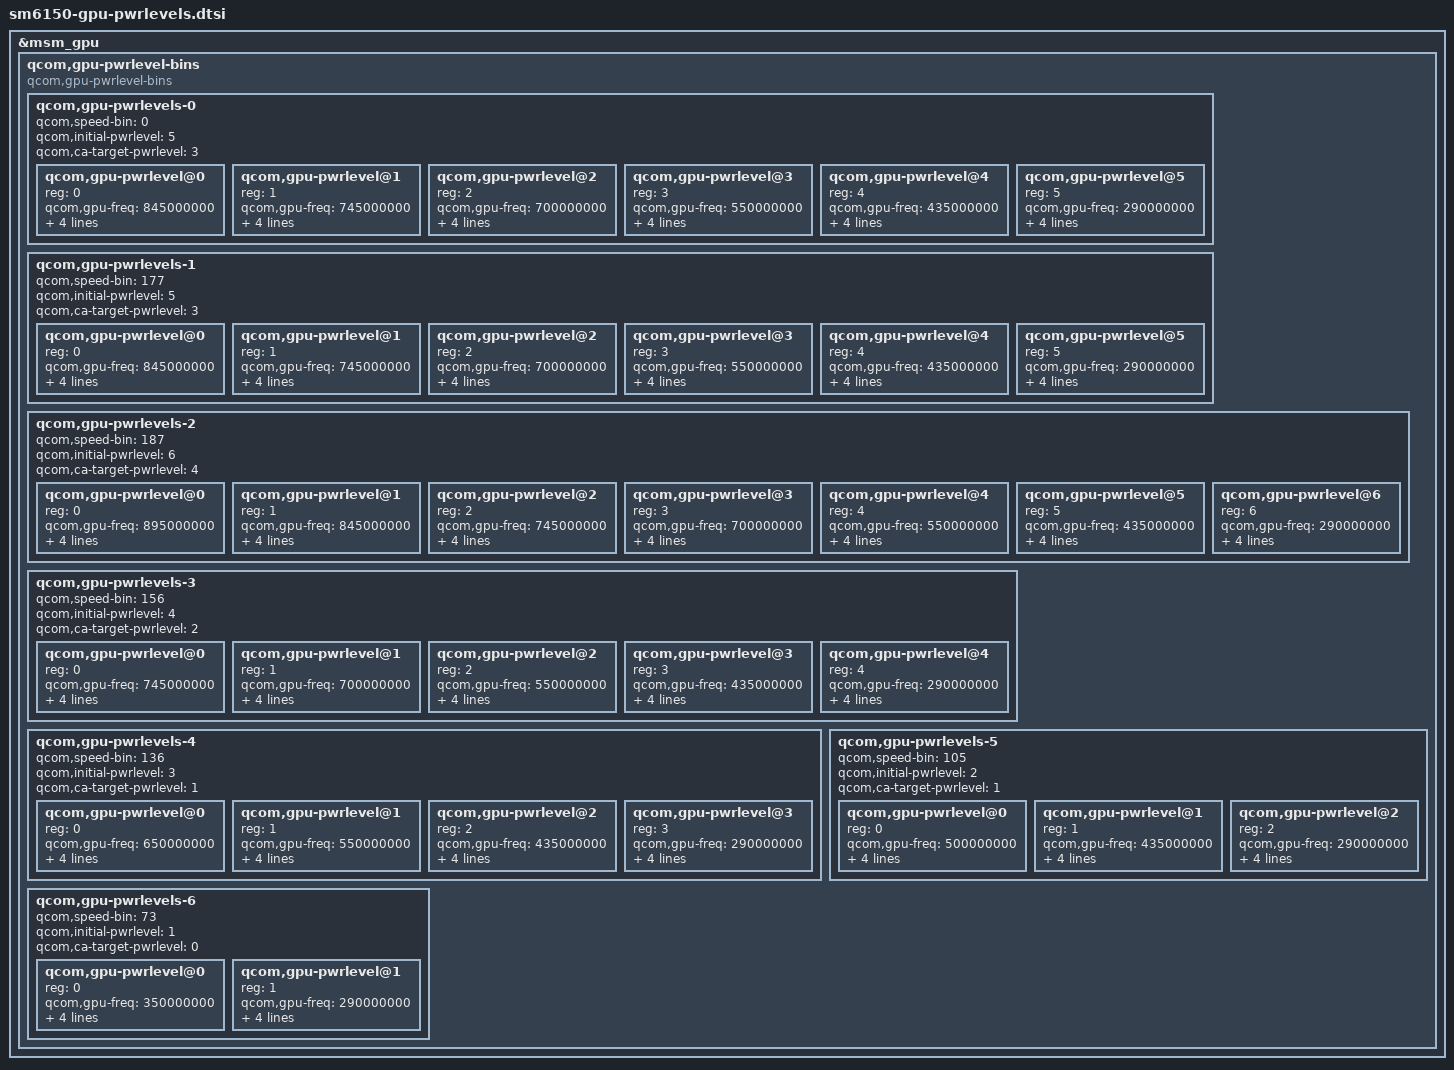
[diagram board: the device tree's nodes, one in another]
// SPDX-License-Identifier: BSD-3-Clause
/*
 * Copyright (c) Qualcomm Technologies, Inc. and/or its subsidiaries.
 */

&msm_gpu {

	/*
	 * Speed-bin zero is default speed bin.
	 * For rest of the speed bins, speed-bin value
	 * is calulated as FMAX/4.8 MHz round up to zero
	 * decimal places.
	 */
	qcom,gpu-pwrlevel-bins {
		#address-cells = <1>;
		#size-cells = <0>;

		compatible="qcom,gpu-pwrlevel-bins";

		qcom,gpu-pwrlevels-0 {
			#address-cells = <1>;
			#size-cells = <0>;

			qcom,speed-bin = <0>;

			qcom,initial-pwrlevel = <5>;
			qcom,ca-target-pwrlevel = <3>;

			/* TURBO */
			qcom,gpu-pwrlevel@0 {
				reg = <0>;
				qcom,gpu-freq = <845000000>;
				qcom,level = <RPMH_REGULATOR_LEVEL_TURBO>;
				qcom,bus-freq = <11>;
				qcom,bus-min = <10>;
				qcom,bus-max = <11>;
			};

			/* NOM L1 */
			qcom,gpu-pwrlevel@1 {
				reg = <1>;
				qcom,gpu-freq = <745000000>;
				qcom,level = <RPMH_REGULATOR_LEVEL_NOM_L1>;
				qcom,bus-freq = <10>;
				qcom,bus-min = <9>;
				qcom,bus-max = <11>;
			};

			/* NOM */
			qcom,gpu-pwrlevel@2 {
				reg = <2>;
				qcom,gpu-freq = <700000000>;
				qcom,level = <RPMH_REGULATOR_LEVEL_NOM>;
				qcom,bus-freq = <9>;
				qcom,bus-min = <8>;
				qcom,bus-max = <10>;
			};

			/* SVS L1 */
			qcom,gpu-pwrlevel@3 {
				reg = <3>;
				qcom,gpu-freq = <550000000>;
				qcom,level = <RPMH_REGULATOR_LEVEL_SVS_L1>;
				qcom,bus-freq = <8>;
				qcom,bus-min = <7>;
				qcom,bus-max = <9>;
			};

			/* SVS */
			qcom,gpu-pwrlevel@4 {
				reg = <4>;
				qcom,gpu-freq = <435000000>;
				qcom,level = <RPMH_REGULATOR_LEVEL_SVS>;
				qcom,bus-freq = <7>;
				qcom,bus-min = <5>;
				qcom,bus-max = <8>;
			};

			/* Low SVS */
			qcom,gpu-pwrlevel@5 {
				reg = <5>;
				qcom,gpu-freq = <290000000>;
				qcom,level = <RPMH_REGULATOR_LEVEL_LOW_SVS>;
				qcom,bus-freq = <4>;
				qcom,bus-min = <4>;
				qcom,bus-max = <5>;
			};
		};

		qcom,gpu-pwrlevels-1 {
			#address-cells = <1>;
			#size-cells = <0>;

			qcom,speed-bin = <177>;

			qcom,initial-pwrlevel = <5>;
			qcom,ca-target-pwrlevel = <3>;

			/* TURBO */
			qcom,gpu-pwrlevel@0 {
				reg = <0>;
				qcom,gpu-freq = <845000000>;
				qcom,level = <RPMH_REGULATOR_LEVEL_TURBO>;
				qcom,bus-freq = <11>;
				qcom,bus-min = <10>;
				qcom,bus-max = <11>;
			};

			/* NOM L1 */
			qcom,gpu-pwrlevel@1 {
				reg = <1>;
				qcom,gpu-freq = <745000000>;
				qcom,level = <RPMH_REGULATOR_LEVEL_NOM_L1>;
				qcom,bus-freq = <10>;
				qcom,bus-min = <9>;
				qcom,bus-max = <11>;
			};

			/* NOM */
			qcom,gpu-pwrlevel@2 {
				reg = <2>;
				qcom,gpu-freq = <700000000>;
				qcom,level = <RPMH_REGULATOR_LEVEL_NOM>;
				qcom,bus-freq = <9>;
				qcom,bus-min = <8>;
				qcom,bus-max = <10>;
			};

			/* SVS L1 */
			qcom,gpu-pwrlevel@3 {
				reg = <3>;
				qcom,gpu-freq = <550000000>;
				qcom,level = <RPMH_REGULATOR_LEVEL_SVS_L1>;
				qcom,bus-freq = <8>;
				qcom,bus-min = <7>;
				qcom,bus-max = <9>;
			};

			/* SVS */
			qcom,gpu-pwrlevel@4 {
				reg = <4>;
				qcom,gpu-freq = <435000000>;
				qcom,level = <RPMH_REGULATOR_LEVEL_SVS>;
				qcom,bus-freq = <7>;
				qcom,bus-min = <5>;
				qcom,bus-max = <8>;
			};

			/* Low SVS */
			qcom,gpu-pwrlevel@5 {
				reg = <5>;
				qcom,gpu-freq = <290000000>;
				qcom,level = <RPMH_REGULATOR_LEVEL_LOW_SVS>;
				qcom,bus-freq = <4>;
				qcom,bus-min = <4>;
				qcom,bus-max = <5>;
			};
		};

		qcom,gpu-pwrlevels-2 {
			#address-cells = <1>;
			#size-cells = <0>;

			qcom,speed-bin = <187>;

			qcom,initial-pwrlevel = <6>;
			qcom,ca-target-pwrlevel = <4>;

			/* TURBO L1 */
			qcom,gpu-pwrlevel@0 {
				reg = <0>;
				qcom,gpu-freq = <895000000>;
				qcom,level = <RPMH_REGULATOR_LEVEL_TURBO_L1>;
				qcom,bus-freq = <11>;
				qcom,bus-min = <10>;
				qcom,bus-max = <11>;
			};
			/* TURBO */
			qcom,gpu-pwrlevel@1 {
				reg = <1>;
				qcom,gpu-freq = <845000000>;
				qcom,level = <RPMH_REGULATOR_LEVEL_TURBO>;
				qcom,bus-freq = <11>;
				qcom,bus-min = <10>;
				qcom,bus-max = <11>;
			};

			/* NOM L1 */
			qcom,gpu-pwrlevel@2 {
				reg = <2>;
				qcom,gpu-freq = <745000000>;
				qcom,level = <RPMH_REGULATOR_LEVEL_NOM_L1>;
				qcom,bus-freq = <10>;
				qcom,bus-min = <9>;
				qcom,bus-max = <11>;
			};

			/* NOM */
			qcom,gpu-pwrlevel@3 {
				reg = <3>;
				qcom,gpu-freq = <700000000>;
				qcom,level = <RPMH_REGULATOR_LEVEL_NOM>;
				qcom,bus-freq = <9>;
				qcom,bus-min = <8>;
				qcom,bus-max = <10>;
			};

			/* SVS L1 */
			qcom,gpu-pwrlevel@4 {
				reg = <4>;
				qcom,gpu-freq = <550000000>;
				qcom,level = <RPMH_REGULATOR_LEVEL_SVS_L1>;
				qcom,bus-freq = <8>;
				qcom,bus-min = <7>;
				qcom,bus-max = <9>;
			};

			/* SVS */
			qcom,gpu-pwrlevel@5 {
				reg = <5>;
				qcom,gpu-freq = <435000000>;
				qcom,level = <RPMH_REGULATOR_LEVEL_SVS>;
				qcom,bus-freq = <7>;
				qcom,bus-min = <5>;
				qcom,bus-max = <8>;
			};

			/* Low SVS */
			qcom,gpu-pwrlevel@6 {
				reg = <6>;
				qcom,gpu-freq = <290000000>;
				qcom,level = <RPMH_REGULATOR_LEVEL_LOW_SVS>;
				qcom,bus-freq = <4>;
				qcom,bus-min = <4>;
				qcom,bus-max = <5>;
			};
		};

		qcom,gpu-pwrlevels-3 {
			#address-cells = <1>;
			#size-cells = <0>;

			qcom,speed-bin = <156>;

			qcom,initial-pwrlevel = <4>;
			qcom,ca-target-pwrlevel = <2>;

			/* NOM L1 */
			qcom,gpu-pwrlevel@0 {
				reg = <0>;
				qcom,gpu-freq = <745000000>;
				qcom,level = <RPMH_REGULATOR_LEVEL_NOM_L1>;
				qcom,bus-freq = <11>;
				qcom,bus-min = <10>;
				qcom,bus-max = <11>;
			};

			/* NOM */
			qcom,gpu-pwrlevel@1 {
				reg = <1>;
				qcom,gpu-freq = <700000000>;
				qcom,level = <RPMH_REGULATOR_LEVEL_NOM>;
				qcom,bus-freq = <9>;
				qcom,bus-min = <8>;
				qcom,bus-max = <10>;
			};

			/* SVS L1 */
			qcom,gpu-pwrlevel@2 {
				reg = <2>;
				qcom,gpu-freq = <550000000>;
				qcom,level = <RPMH_REGULATOR_LEVEL_SVS_L1>;
				qcom,bus-freq = <8>;
				qcom,bus-min = <7>;
				qcom,bus-max = <9>;
			};

			/* SVS */
			qcom,gpu-pwrlevel@3 {
				reg = <3>;
				qcom,gpu-freq = <435000000>;
				qcom,level = <RPMH_REGULATOR_LEVEL_SVS>;
				qcom,bus-freq = <7>;
				qcom,bus-min = <5>;
				qcom,bus-max = <8>;
			};

			/* Low SVS */
			qcom,gpu-pwrlevel@4 {
				reg = <4>;
				qcom,gpu-freq = <290000000>;
				qcom,level = <RPMH_REGULATOR_LEVEL_LOW_SVS>;
				qcom,bus-freq = <4>;
				qcom,bus-min = <4>;
				qcom,bus-max = <5>;
			};
		};

		qcom,gpu-pwrlevels-4 {
			#address-cells = <1>;
			#size-cells = <0>;

			qcom,speed-bin = <136>;

			qcom,initial-pwrlevel = <3>;
			qcom,ca-target-pwrlevel = <1>;

			/* NOM */
			qcom,gpu-pwrlevel@0 {
				reg = <0>;
				qcom,gpu-freq = <650000000>;
				qcom,level = <RPMH_REGULATOR_LEVEL_NOM>;
				qcom,bus-freq = <9>;
				qcom,bus-min = <8>;
				qcom,bus-max = <10>;
			};

			/* SVS L1 */
			qcom,gpu-pwrlevel@1 {
				reg = <1>;
				qcom,gpu-freq = <550000000>;
				qcom,level = <RPMH_REGULATOR_LEVEL_SVS_L1>;
				qcom,bus-freq = <8>;
				qcom,bus-min = <7>;
				qcom,bus-max = <9>;
			};

			/* SVS */
			qcom,gpu-pwrlevel@2 {
				reg = <2>;
				qcom,gpu-freq = <435000000>;
				qcom,level = <RPMH_REGULATOR_LEVEL_SVS>;
				qcom,bus-freq = <7>;
				qcom,bus-min = <5>;
				qcom,bus-max = <8>;
			};

			/* Low SVS */
			qcom,gpu-pwrlevel@3 {
				reg = <3>;
				qcom,gpu-freq = <290000000>;
				qcom,level = <RPMH_REGULATOR_LEVEL_LOW_SVS>;
				qcom,bus-freq = <4>;
				qcom,bus-min = <4>;
				qcom,bus-max = <5>;
			};
		};

		qcom,gpu-pwrlevels-5 {
			#address-cells = <1>;
			#size-cells = <0>;

			qcom,speed-bin = <105>;

			qcom,initial-pwrlevel = <2>;
			qcom,ca-target-pwrlevel = <1>;

			/* SVS L1 */
			qcom,gpu-pwrlevel@0 {
				reg = <0>;
				qcom,gpu-freq = <500000000>;
				qcom,level = <RPMH_REGULATOR_LEVEL_SVS_L1>;
				qcom,bus-freq = <8>;
				qcom,bus-min = <7>;
				qcom,bus-max = <9>;
			};

			/* SVS */
			qcom,gpu-pwrlevel@1 {
				reg = <1>;
				qcom,gpu-freq = <435000000>;
				qcom,level = <RPMH_REGULATOR_LEVEL_SVS>;
				qcom,bus-freq = <7>;
				qcom,bus-min = <5>;
				qcom,bus-max = <8>;
			};

			/* Low SVS */
			qcom,gpu-pwrlevel@2 {
				reg = <2>;
				qcom,gpu-freq = <290000000>;
				qcom,level = <RPMH_REGULATOR_LEVEL_LOW_SVS>;
				qcom,bus-freq = <4>;
				qcom,bus-min = <4>;
				qcom,bus-max = <5>;
			};
		};

		qcom,gpu-pwrlevels-6 {
			#address-cells = <1>;
			#size-cells = <0>;

			qcom,speed-bin = <73>;

			qcom,initial-pwrlevel = <1>;
			qcom,ca-target-pwrlevel = <0>;

			/* SVS */
			qcom,gpu-pwrlevel@0 {
				reg = <0>;
				qcom,gpu-freq = <350000000>;
				qcom,level = <RPMH_REGULATOR_LEVEL_SVS>;
				qcom,bus-freq = <7>;
				qcom,bus-min = <5>;
				qcom,bus-max = <8>;
			};

			/* Low SVS */
			qcom,gpu-pwrlevel@1 {
				reg = <1>;
				qcom,gpu-freq = <290000000>;
				qcom,level = <RPMH_REGULATOR_LEVEL_LOW_SVS>;
				qcom,bus-freq = <4>;
				qcom,bus-min = <4>;
				qcom,bus-max = <5>;
			};
		};
	};
};
